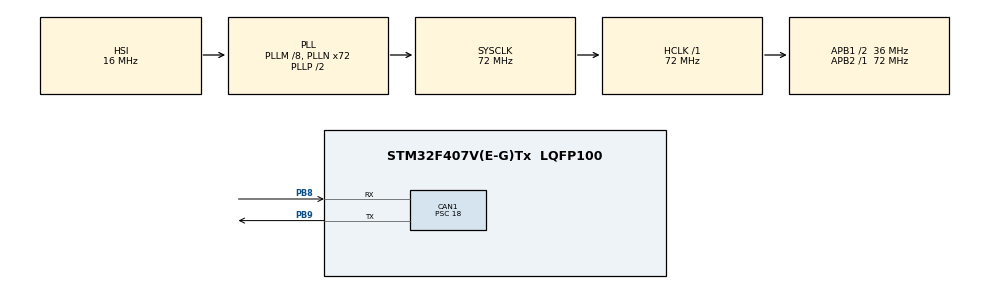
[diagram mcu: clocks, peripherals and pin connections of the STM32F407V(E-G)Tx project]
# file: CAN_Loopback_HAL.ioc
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CAN1.BS1=CAN_BS1_2TQ
CAN1.CalculateBaudRate=500000
CAN1.CalculateTimeBit=2000
CAN1.CalculateTimeQuantum=500.0
CAN1.Mode=CAN_MODE_LOOPBACK
CAN1.Prescaler=18
Mcu.Family=STM32F4
Mcu.Name=STM32F407V(E-G)Tx
Mcu.Package=LQFP100
NVIC.PriorityGroup=NVIC_PRIORITYGROUP_0
PA13.Mode=Serial_Wire
PA13.Signal=SYS_JTMS-SWDIO
PA14.Mode=Serial_Wire
PA14.Signal=SYS_JTCK-SWCLK
PB8.Mode=CAN_Activate
PB8.Signal=CAN1_RX
PB9.Mode=CAN_Activate
PB9.Signal=CAN1_TX
PH0-OSC_IN.Mode=HSE-External-Oscillator
PH0-OSC_IN.Signal=RCC_OSC_IN
PH1-OSC_OUT.Mode=HSE-External-Oscillator
PH1-OSC_OUT.Signal=RCC_OSC_OUT
ProjectManager.HeapSize=0x200
ProjectManager.StackSize=0x400
ProjectManager.TargetToolchain=STM32CubeIDE
RCC.48MHZClocksFreq_Value=20571428.57142857
RCC.AHBFreq_Value=72000000
RCC.APB1CLKDivider=RCC_HCLK_DIV2
RCC.APB1Freq_Value=36000000
RCC.APB1TimFreq_Value=72000000
RCC.APB2Freq_Value=72000000
RCC.APB2TimFreq_Value=72000000
RCC.CortexFreq_Value=72000000
RCC.HCLKFreq_Value=72000000
RCC.HSE_VALUE=8000000
RCC.HSI_VALUE=16000000
RCC.LSE_VALUE=32768
RCC.PLLM=8
RCC.PLLN=72
RCC.PLLQ=7
RCC.SYSCLKFreq_VALUE=72000000
RCC.SYSCLKSource=RCC_SYSCLKSOURCE_PLLCLK
RCC.VCOOutputFreq_Value=144000000
board=STM32F407G-DISC1

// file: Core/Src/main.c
/* USER CODE BEGIN Header */
/**
  ******************************************************************************
  * @file           : main.c
  * @brief          : Main program body
  ******************************************************************************
  * @attention
  *
  * Copyright (c) 2024 STMicroelectronics.
  * All rights reserved.
  *
  * This software is licensed under terms that can be found in the LICENSE file
  * in the root directory of this software component.
  * If no LICENSE file comes with this software, it is provided AS-IS.
  *
  ******************************************************************************
  */
/* USER CODE END Header */
#include "main.h"

CAN_HandleTypeDef hcan1;

/* USER CODE BEGIN PV */
CAN_TxHeaderTypeDef TxHeader;
uint8_t Txdata[5] = "Apple";
uint32_t myTxMailbox;

CAN_RxHeaderTypeDef RxHeader;
uint8_t RxData[5];
/* USER CODE END PV */

void SystemClock_Config(void);
static void MX_GPIO_Init(void);
static void MX_CAN1_Init(void);

int main(void)
{

  /* MCU Configuration--------------------------------------------------------*/

  /* Reset of all peripherals, Initializes the Flash interface and the Systick. */
  HAL_Init();

  /* Configure the system clock */
  SystemClock_Config();

  /* Initialize all configured peripherals */
  MX_GPIO_Init();
  MX_CAN1_Init();

  /* USER CODE BEGIN 2 */
  // Set up the CAN filter configuration
  CAN_FilterTypeDef canFilterConfig;
  canFilterConfig.FilterBank = 0; // Select a filter bank (0 - 13)
  canFilterConfig.FilterMode = CAN_FILTERMODE_IDMASK;
  canFilterConfig.FilterScale = CAN_FILTERSCALE_32BIT;
  canFilterConfig.FilterIdHigh = 0x0000;  // Accept all IDs
  canFilterConfig.FilterIdLow = 0x0000;
  canFilterConfig.FilterMaskIdHigh = 0x0000;  // Accept all IDs
  canFilterConfig.FilterMaskIdLow = 0x0000;
  canFilterConfig.FilterFIFOAssignment = CAN_RX_FIFO0; // Assign the filter to FIFO 0
  canFilterConfig.FilterActivation = ENABLE;
  canFilterConfig.SlaveStartFilterBank = 14;

  if (HAL_CAN_ConfigFilter(&hcan1, &canFilterConfig) != HAL_OK)
  {
    // Filter configuration Error
    Error_Handler();
  }

  // Start CAN
  if (HAL_CAN_Start(&hcan1) != HAL_OK)
  {
    // Start Error
    Error_Handler();
  }

  // Activate the notification for message reception
  if (HAL_CAN_ActivateNotification(&hcan1, CAN_IT_RX_FIFO0_MSG_PENDING) != HAL_OK)
  {
    // Notification Error
    Error_Handler();
  }

  // Set up CAN transmit header
  TxHeader.StdId = 0x100;  // Standard Identifier
  TxHeader.ExtId = 0x01;   // Extended Identifier (not used in this case)
  TxHeader.RTR = CAN_RTR_DATA; // Data Frame
  TxHeader.IDE = CAN_ID_STD; // Standard ID
  TxHeader.DLC = 5; // Data Length Code (set to match Txdata length)
  /* USER CODE END 2 */

  /* Infinite loop */
  /* USER CODE BEGIN WHILE */
  while (1)
  {
    // Transmit CAN message if mailbox is available
    if (HAL_CAN_GetTxMailboxesFreeLevel(&hcan1) > 0)
    {
      if (HAL_CAN_AddTxMessage(&hcan1, &TxHeader, Txdata, &myTxMailbox) != HAL_OK)
      {
        // Transmission Error
        Error_Handler();
      }
    }

    // Check if a CAN message is received
    if (HAL_CAN_GetRxFifoFillLevel(&hcan1, CAN_RX_FIFO0) > 0)
    {
      if (HAL_CAN_GetRxMessage(&hcan1, CAN_RX_FIFO0, &RxHeader, RxData) == HAL_OK)
      {
        // Process the received message (RxData)
        // You can add your code here to handle the received data
      }
      else
      {
        // Reception Error
        Error_Handler();
      }
    }

    HAL_Delay(500); // Delay to allow periodic transmission/reception
  }
  /* USER CODE END WHILE */

}

void SystemClock_Config(void)
{
  RCC_OscInitTypeDef RCC_OscInitStruct = {0};
  RCC_ClkInitTypeDef RCC_ClkInitStruct = {0};

  /** Configure the main internal regulator output voltage
  */
  __HAL_RCC_PWR_CLK_ENABLE();
  __HAL_PWR_VOLTAGESCALING_CONFIG(PWR_REGULATOR_VOLTAGE_SCALE1);

  /** Initializes the RCC Oscillators according to the specified parameters
  * in the RCC_OscInitTypeDef structure.
  */
  RCC_OscInitStruct.OscillatorType = RCC_OSCILLATORTYPE_HSI;
  RCC_OscInitStruct.HSIState = RCC_HSI_ON;
  RCC_OscInitStruct.HSICalibrationValue = RCC_HSICALIBRATION_DEFAULT;
  RCC_OscInitStruct.PLL.PLLState = RCC_PLL_ON;
  RCC_OscInitStruct.PLL.PLLSource = RCC_PLLSOURCE_HSI;
  RCC_OscInitStruct.PLL.PLLM = 8;
  RCC_OscInitStruct.PLL.PLLN = 72;
  RCC_OscInitStruct.PLL.PLLP = RCC_PLLP_DIV2;
  RCC_OscInitStruct.PLL.PLLQ = 7;
  if (HAL_RCC_OscConfig(&RCC_OscInitStruct) != HAL_OK)
  {
    Error_Handler();
  }

  /** Initializes the CPU, AHB and APB buses clocks
  */
  RCC_ClkInitStruct.ClockType = RCC_CLOCKTYPE_HCLK|RCC_CLOCKTYPE_SYSCLK
                              |RCC_CLOCKTYPE_PCLK1|RCC_CLOCKTYPE_PCLK2;
  RCC_ClkInitStruct.SYSCLKSource = RCC_SYSCLKSOURCE_PLLCLK;
  RCC_ClkInitStruct.AHBCLKDivider = RCC_SYSCLK_DIV1;
  RCC_ClkInitStruct.APB1CLKDivider = RCC_HCLK_DIV2;
  RCC_ClkInitStruct.APB2CLKDivider = RCC_HCLK_DIV1;

  if (HAL_RCC_ClockConfig(&RCC_ClkInitStruct, FLASH_LATENCY_2) != HAL_OK)
  {
    Error_Handler();
  }
}

static void MX_CAN1_Init(void)
{
  hcan1.Instance = CAN1;
  hcan1.Init.Prescaler = 18;
  hcan1.Init.Mode = CAN_MODE_LOOPBACK; // Set mode to loopback for testing
  hcan1.Init.SyncJumpWidth = CAN_SJW_1TQ;
  hcan1.Init.TimeSeg1 = CAN_BS1_2TQ;
  hcan1.Init.TimeSeg2 = CAN_BS2_1TQ;
  hcan1.Init.TimeTriggeredMode = DISABLE;
  hcan1.Init.AutoBusOff = DISABLE;
  hcan1.Init.AutoWakeUp = DISABLE;
  hcan1.Init.AutoRetransmission = DISABLE;
  hcan1.Init.ReceiveFifoLocked = DISABLE;
  hcan1.Init.TransmitFifoPriority = DISABLE;
  if (HAL_CAN_Init(&hcan1) != HAL_OK)
  {
    Error_Handler();
  }
}

static void MX_GPIO_Init(void)
{
  /* GPIO Ports Clock Enable */
  __HAL_RCC_GPIOH_CLK_ENABLE();
  __HAL_RCC_GPIOA_CLK_ENABLE();
  __HAL_RCC_GPIOB_CLK_ENABLE();
}

void Error_Handler(void)
{
  /* User can add his own implementation to report the HAL error return state */
  __disable_irq();
  while (1)
  {
  }
}
